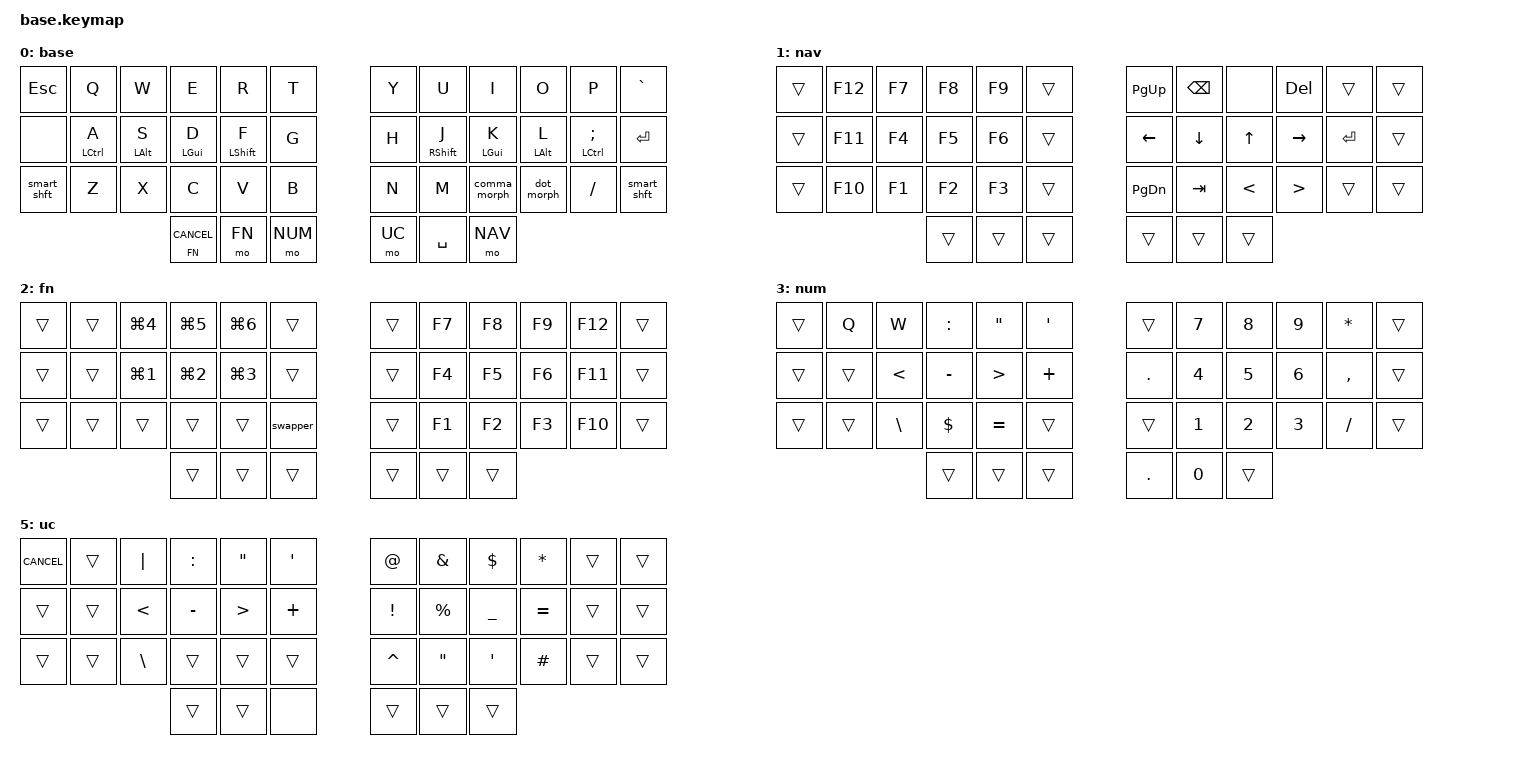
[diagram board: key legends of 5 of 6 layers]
#include <behaviors.dtsi>
#include <dt-bindings/zmk/keys.h>
#if CONFIG_WIRELESS
    #include <dt-bindings/zmk/bt.h>
    #define _BT_SEL_KEYS_ &bt BT_SEL 0 &bt BT_SEL 1 &bt BT_SEL 2 &bt BT_SEL 3 &bt BT_CLR
#else
    #define _BT_SEL_KEYS_ &trans &trans &trans &trans &trans
#endif

#include "../zmk-nodefree-config/helper.h"

#define DEF 0
#define NAV 1
#define FN 2
#define NUM 3
#define SYS 4
#define UC 5

#include "combos.dtsi"  // requires layer aliases
// #include "extra_keys.h"

#define ___ &trans
#define XXX &none

/* Global settings */

#define QUICK_TAP_MS 175

&sk {  // sticky-key config
    release-after-ms = <900>;  // release after 0.6s
    quick-release;             // no double capitalization when rolling keys
};

&sl {  // sticky-layer config
    ignore-modifiers;          // allow chording sticky mods & layers
};

&lt {  // layer-tap config
    flavor = "balanced";
    tapping-term-ms = <200>;
    quick-tap-ms = <QUICK_TAP_MS>;
};

/* Homerow mods */

#define KEYS_L LT0 LT1 LT2 LT3 LT4 LT5 LM0 LM1 LM2 LM3 LM4 LM5 LB0 LB1 LB2 LB3 LB4 LB5  // left hand
#define KEYS_R RT0 RT1 RT2 RT3 RT4 RT5 RM0 RM1 RM2 RM3 RM4 RM5 RB0 RB1 RB2 RB3 RB4 RB5 // right hand
#define THUMBS LH2 LH1 LH0 RH0 RH1 RH2                                      // thumbs

#define MAKE_HRM(NAME, HOLD, TAP, TRIGGER_POS) \
    ZMK_BEHAVIOR(NAME, hold_tap, \
        flavor = "balanced"; \
        tapping-term-ms = <280>; \
        quick-tap-ms = <QUICK_TAP_MS>; \
        require-prior-idle-ms = <150>; \
        bindings = <HOLD>, <TAP>; \
        hold-trigger-key-positions = <TRIGGER_POS>; \
        hold-trigger-on-release; \
    )
MAKE_HRM(hml, &kp, &kp, KEYS_R THUMBS)  // left-hand HRMs
MAKE_HRM(hmr, &kp, &kp, KEYS_L THUMBS)  // right-hand HRMs

MAKE_HRM(hmr_lpar_lt, &kp, &lpar_lt, KEYS_L THUMBS)    // "    "   "   "
MAKE_HRM(hmr_rpar_gt, &kp, &rpar_gt, KEYS_L THUMBS)    // "    "   "   "


// tap: sticky-shift | shift + tap/ double-tap: caps-word | hold: shift
ZMK_BEHAVIOR(smart_shft, mod_morph,
    bindings = <&sk LSHFT>, <&caps_word>;
    mods = <(MOD_LSFT)>;
)
&caps_word {  // mods deactivate caps-word, requires PR #1451
    /delete-property/ ignore-modifiers;
};

/* Custom behaviors */

// Alt+Tab swapper, requires PR #1366
ZMK_BEHAVIOR(swapper, tri_state,
    bindings = <&kt LGUI>, <&kp TAB>, <&kt LGUI>;
    ignored-key-positions = <LT2>;
)

// Sticky layer + sticky shift (workaround for issue #1421)
ZMK_BEHAVIOR(sls, sticky_key,
    release-after-ms = <1000>;
    bindings = <&uc_shift>;
    ignore-modifiers;
)
ZMK_BEHAVIOR(uc_shift, macro,
    wait-ms = <0>;
    tap-ms = <1>;
    bindings = <&macro_press &mo UC &kp LSHFT>
             , <&macro_pause_for_release>
             , <&macro_release &mo UC &kp LSHFT>;
)

// reuse basic mod-morph scheme
#define SIMPLE_MORPH(NAME, MOD, BINDING1, BINDING2) \
    ZMK_BEHAVIOR(NAME, mod_morph, \
        mods = <(MOD_L ## MOD|MOD_R ## MOD)>; \
        bindings = <BINDING1>, <BINDING2>; \
    )

// tap: comma | shift + tap: pipe
SIMPLE_MORPH(comma_morph, SFT, &kp COMMA, &kp PIPE)

// tap: dot | shift + tap: > 
SIMPLE_MORPH(dot_morph, SFT, &kp DOT, &kp GT)

// tap: left-parenthesis | shft + tap: less-than
SIMPLE_MORPH(lpar_lt, SFT, &kp LPAR, &kp LT)

// tap: right-parenthesis | shft + tap: greater-than
SIMPLE_MORPH(rpar_gt, SFT, &kp RPAR, &kp GT)

// misc aliases
#define CANCEL      &kp K_CANCEL             // cancel caps-word, num-word 

/* Keymap */

ZMK_CONDITIONAL_LAYER(FN NUM, SYS)  // FN + NUM --> SYS

ZMK_LAYER(base,
//╭──────┬───────────────┬─────────────┬─────────────┬─────────────┬─────────────╮  ╭─────────────┬─────────────┬─────────────┬─────────────┬─────────────┬────────╮
 &kp ESC       &kp Q         &kp W         &kp E         &kp R         &kp T            &kp Y         &kp U         &kp I         &kp O         &kp P        &kp GRAVE
//├──────┼───────────────┼─────────────┼─────────────┼─────────────┼─────────────┤  ├─────────────┼─────────────┼─────────────┼─────────────┼─────────────┴────────┤
    XXX        &hml LCTRL A   &hml LALT S   &hml LGUI D  &hml LSHFT F  &kp G            &kp H         &hmr RSHFT J  &hmr LGUI K  &hmr LALT L &hmr LCTRL SEMI   &kp RET
//├──────┼───────────────┼─────────────┼─────────────┼─────────────┼─────────────┤  ├─────────────┼─────────────┼─────────────┼─────────────┼─────────────┴────────┤
&smart_shft    &kp Z         &kp X         &kp C         &kp V         &kp B            &kp N         &kp M      &comma_morph  &dot_morph    &kp FSLH     &smart_shft
//├──────┤ ╰─────────────┼─────────────┴─────────────┼─────────────┼─────────────┤  ├─────────────┼─────────────┼─────────────┴───────────────────────────┴────────╯
                                       &lt FN K_CANCEL  &mo FN         &mo NUM          &mo UC        &kp SPACE       &mo NAV     
//                                     ╰─────────────┴─────────────┴─────────────╯  ╰─────────────┴─────────────┴─────────────╯
)

ZMK_LAYER(nav,
//╭──────┬───────────────┬─────────────┬─────────────┬─────────────┬─────────────╮  ╭─────────────┬─────────────┬─────────────┬─────────────┬─────────────┬────────╮
    ___      &kp F12       &kp F7        &kp F8        &kp F9        ___              &kp PG_UP     &kp BSPC        XXX         &kp DEL       ___             ___  
//├──────┼───────────────┼─────────────┼─────────────┼─────────────┼─────────────┤  ├─────────────┼─────────────┼─────────────┼─────────────┼─────────────┼────────┤
    ___      &kp F11       &kp F4        &kp F5        &kp F6        ___              &kp LEFT      &kp DOWN      &kp UP        &kp RIGHT     &kp RET         ___ 
//├──────┼───────────────┼─────────────┼─────────────┼─────────────┼─────────────┤  ├─────────────┼─────────────┼─────────────┼─────────────┼─────────────┼────────┤
    ___      &kp F10       &kp F1        &kp F2        &kp F3        ___              &kp PG_DN     &kp TAB       &kp LT        &kp GT        ___             ___ 
//├──────┤ ╰─────────────┼─────────────┴─────────────┼─────────────┼─────────────┤  ├─────────────┼─────────────┼─────────────┴───────────────────────────┴────────┤
                                           ___         ___           ___              ___             ___             ___                                  
//                                     ╰─────────────┴─────────────┴─────────────╯  ╰─────────────┴─────────────┴─────────────╯                        
)

ZMK_LAYER(fn,
//╭──────┬───────────────┬─────────────┬─────────────┬─────────────┬─────────────╮  ╭─────────────┬─────────────┬─────────────┬─────────────┬─────────────┬────────╮
    ___        ___         &kp LG(N4)    &kp LG(N5)     &kp LG(N6)   ___              ___           &kp F7          &kp F8         &kp F9       &kp F12      ___ 
//├──────┼───────────────┼─────────────┼─────────────┼─────────────┼─────────────┤  ├─────────────┼─────────────┼─────────────┼─────────────┼─────────────┼────────┤
    ___        ___         &kp LG(N1)    &kp LG(N2)     &kp LG(N3)   ___              ___           &kp F4          &kp F5         &kp F6       &kp F11      ___ 
//├──────┼───────────────┼─────────────┼─────────────┼─────────────┼─────────────┤  ├─────────────┼─────────────┼─────────────┼─────────────┼─────────────┼────────┤
    ___        ___           ___           ___           ___           &swapper          ___        &kp F1          &kp F2         &kp F3       &kp F10      ___ 
//├──────┤ ╰─────────────┼─────────────┴─────────────┼─────────────┼─────────────┤  ├─────────────┼─────────────┼─────────────┴───────────────────────────┴────────┤
                                           ___         ___            &trans          ___            ___         ___                                          
//                                     ╰─────────────┴─────────────┴─────────────╯  ╰─────────────┴─────────────┴─────────────╯                                     
)

ZMK_LAYER(num,
//╭──────┬───────────────┬─────────────┬─────────────┬─────────────┬─────────────╮  ╭─────────────┬─────────────┬─────────────┬─────────────┬─────────────┬────────╮
    ___     &kp Q         &kp W        &kp COLON      &kp DQT     &kp SQT               ___            &kp N7        &kp N8        &kp N9     &kp STAR        ___ 
//├──────┼───────────────┼─────────────┼─────────────┼─────────────┼─────────────┤  ├─────────────┼─────────────┼─────────────┼─────────────┼─────────────┼────────┤
    ___        ___          &kp LT       &kp MINUS     &kp GT       &kp PLUS             &kp DOT       &kp N4       &kp N5       &kp N6       &kp COMMA        ___
//├──────┼───────────────┼─────────────┼─────────────┼─────────────┼─────────────┤  ├─────────────┼─────────────┼─────────────┼─────────────┼─────────────┼────────┤
    ___      ___           &kp BSLH        &kp DLLR       &kp EQUAL         ___          ___           &kp N1        &kp N2        &kp N3        &kp FSLH        ___ 
//├──────┤ ╰─────────────┼─────────────┴─────────────┼─────────────┼─────────────┤  ├─────────────┼─────────────┼─────────────┴───────────────────────────┴────────┤
                                            ___       ___           ___                 &kp DOT        &kp N0            ___                                              
//                                     ╰─────────────┴─────────────┴─────────────╯  ╰─────────────┴─────────────┴─────────────╯                                       
)

ZMK_LAYER(sys,
//╭──────┬───────────────┬─────────────┬─────────────┬─────────────┬─────────────╮  ╭─────────────┬─────────────┬─────────────┬─────────────┬─────────────┬────────╮
    ___                                 _BT_SEL_KEYS_                                 ___                            _BT_SEL_KEYS_                                 
//├──────┼───────────────┼─────────────┼─────────────┼─────────────┼─────────────┤  ├─────────────┼─────────────┼─────────────┼─────────────┼─────────────┼────────┤
    ___      ___           ___           ___           ___           &bootloader      &bootloader   ___           ___           ___           ___             ___ 
//├──────┼───────────────┼─────────────┼─────────────┼─────────────┼─────────────┤  ├─────────────┼─────────────┼─────────────┼─────────────┼─────────────┼────────┤
    ___      ___           ___           ___           ___           &sys_reset       &sys_reset    ___           ___           ___           ___             ___ 
//├──────┤ ╰─────────────┼─────────────┴─────────────┼─────────────┼─────────────┤  ├─────────────┼─────────────┼─────────────┴───────────────────────────┴────────┤
                                           ___         ___           ___              ___           ___             ___                                            
//                                     ╰─────────────┴─────────────┴─────────────╯  ╰─────────────┴─────────────┴─────────────╯                                     
)

ZMK_LAYER(uc,
//╭──────┬───────────────┬─────────────┬─────────────┬─────────────┬─────────────╮  ╭─────────────┬─────────────┬─────────────┬─────────────┬─────────────┬────────╮
    CANCEL     ___            &kp PIPE     &kp COLON     &kp DQT      &kp SQT           &kp AT        &kp AMPS     &kp DLLR        &kp STAR     ___          ___               
//├──────┼───────────────┼─────────────┼─────────────┼─────────────┼─────────────┤  ├─────────────┼─────────────┼─────────────┼─────────────┼─────────────┼────────┤
    ___        ___            &kp LT       &kp MINUS     &kp GT       &kp PLUS        &kp EXCL     &kp PERCENT   &kp UNDER         &kp EQUAL      ___         ___      
//├──────┼───────────────┼─────────────┼─────────────┼─────────────┼─────────────┤  ├─────────────┼─────────────┼─────────────┼─────────────┼─────────────┼────────┤
    ___        ___             &kp BSLH         ___       ___            ___          &kp CARET       &kp DQT      &kp SQT         &kp HASH        ___          ___    
//├──────┤ ╰─────────────┼─────────────┴─────────────┼─────────────┼─────────────┤  ├─────────────┼─────────────┼─────────────┴───────────────────────────┴────────┤
                                           ___         ___           XXX          ___           ___              ___                                             
//                                     ╰─────────────┴─────────────┴─────────────╯  ╰───────────────────────────┴─────────────╯                                      
)

/* vim: set ft=c tw=174: */
